# STM32H757_CM7 register map
File version: 1.3
CPU: CM7 r0p1, little endian, MPU, FPU, 4 interrupt priority bits
Registers are 32-bit, read-write, reset 0x0 unless marked. A register's access mark holds for its fields unless they carry their own. Offsets are from the block's base; [hi:lo] are bit positions; 'fields as' and 'values as' point back to an identical list.

## ADC3_Common — Analog-to-Digital Converter
Base 0x58026300
Same registers: ADC12_Common 0x40022300
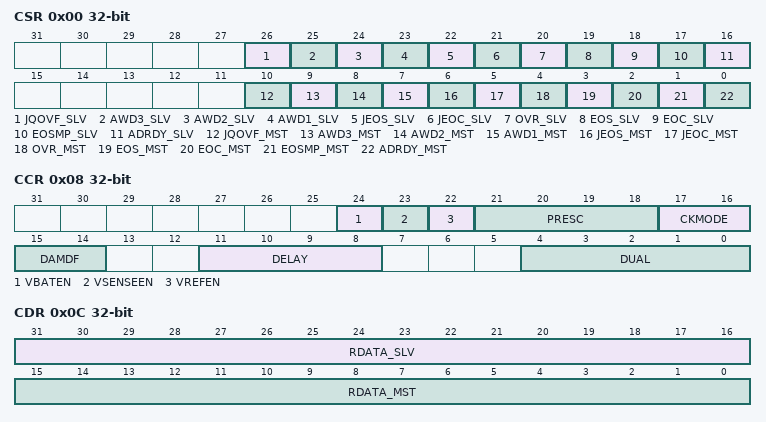
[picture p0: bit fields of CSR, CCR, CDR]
0x00 CSR ro — ADC Common status register
  [26] JQOVF_SLV — Injected Context Queue Overflow flag of the slave ADC
    0=NoOverflow (No injected context queue overflow has occurred); 1=Overflow (Injected context queue overflow has occurred)
  [25] AWD3_SLV — Analog watchdog 3 flag of the slave ADC
    0=NoEvent (No analog watchdog event occurred); 1=Event (Analog watchdog event occurred)
  [24] AWD2_SLV — Analog watchdog 2 flag of the slave ADC
    values as AWD3_SLV
  [23] AWD1_SLV — Analog watchdog 1 flag of the slave ADC
    values as AWD3_SLV
  [22] JEOS_SLV — End of injected sequence flag of the slave ADC
    0=NotComplete (Injected sequence is not complete); 1=Complete (Injected sequence complete)
  [21] JEOC_SLV — End of injected conversion flag of the slave ADC
    0=NotComplete (Injected conversion is not complete); 1=Complete (Injected conversion complete)
  [20] OVR_SLV — Overrun flag of the slave ADC
    0=No overrun occurred; 1=Overrun occurred
  [19] EOS_SLV — End of regular sequence flag of the slave ADC
    0=NotComplete (Regular sequence is not complete); 1=Complete (Regular sequence complete)
  [18] EOC_SLV — End of regular conversion of the slave ADC
    0=NotComplete (Regular conversion is not complete); 1=Complete (Regular conversion complete)
  [17] EOSMP_SLV — End of Sampling phase flag of the slave ADC
    0=NotEnded (End of sampling phase no yet reached); 1=Ended (End of sampling phase reached)
  [16] ADRDY_SLV — Slave ADC ready
    0=NotReady (ADC is not ready to start conversion); 1=Ready (ADC is ready to start conversion)
  [10] JQOVF_MST — Injected Context Queue Overflow flag of the master ADC
    values as JQOVF_SLV
  [9] AWD3_MST — Analog watchdog 3 flag of the master ADC
    values as AWD3_SLV
  [8] AWD2_MST — Analog watchdog 2 flag of the master ADC
    values as AWD3_SLV
  [7] AWD1_MST — Analog watchdog 1 flag of the master ADC
    values as AWD3_SLV
  [6] JEOS_MST — End of injected sequence flag of the master ADC
    values as JEOS_SLV
  [5] JEOC_MST — End of injected conversion flag of the master ADC
    values as JEOC_SLV
  [4] OVR_MST — Overrun flag of the master ADC
    0=No overrun occurred; 1=Overrun occurred
  [3] EOS_MST — End of regular sequence flag of the master ADC
    values as EOS_SLV
  [2] EOC_MST — End of regular conversion of the master ADC
    values as EOC_SLV
  [1] EOSMP_MST — End of Sampling phase flag of the master ADC
    values as EOSMP_SLV
  [0] ADRDY_MST — Master ADC ready
    values as ADRDY_SLV
0x08 CCR — ADC common control register
  [24] VBATEN — VBAT enable
    0=Disabled (V_BAT channel disabled); 1=Enabled (V_BAT channel enabled)
  [23] VSENSEEN — Temperature sensor enable
    0=Disabled (Temperature sensor channel disabled); 1=Enabled (Temperature sensor channel enabled)
  [22] VREFEN — VREFINT enable
    0=Disabled (V_REFINT channel disabled); 1=Enabled (V_REFINT channel enabled)
  [21:18] PRESC — ADC prescaler
    0=Div1 (adc_ker_ck_input not divided); 1=Div2 (adc_ker_ck_input divided by 2); 2=Div4 (adc_ker_ck_input divided by 4); 3=Div6 (adc_ker_ck_input divided by 6); 4=Div8 (adc_ker_ck_input divided by 8); 5=Div10 (adc_ker_ck_input divided by 10); 6=Div12 (adc_ker_ck_input divided by 12); 7=Div16 (adc_ker_ck_input divided by 16); 8=Div32 (adc_ker_ck_input divided by 32); 9=Div64 (adc_ker_ck_input divided by 64); 10=Div128 (adc_ker_ck_input divided by 128); 11=Div256 (adc_ker_ck_input divided by 256)
  [17:16] CKMODE — ADC clock mode
    0=Asynchronous (Use Kernel Clock adc_ker_ck_input divided by PRESC. Asynchronous to AHB clock); 1=SyncDiv1 (Use AHB clock rcc_hclk3. In this case rcc_hclk must equal sys_d1cpre_ck); 2=SyncDiv2 (Use AHB clock rcc_hclk3 divided by 2); 3=SyncDiv4 (Use AHB clock rcc_hclk3 divided by 4)
  [15:14] DAMDF — Dual ADC Mode Data Format
    0=NoPack (Without data packing, CDR/CDR2 not used); 2=Format32to10 (CDR formatted for 32-bit down to 10-bit resolution); 3=Format8 (CDR formatted for 8-bit resolution)
  [11:8] DELAY — Delay between 2 sampling phases
  [4:0] DUAL — Dual ADC mode selection
    0=Independent mode; 1=DualRJ (Dual, combined regular simultaneous + injected simultaneous mode); 2=DualRA (Dual, combined regular simultaneous + alternate trigger mode); 3=DualIJ (Dual, combined interleaved mode + injected simultaneous mode); 5=DualJ (Dual, injected simultaneous mode only); 6=Dual, regular simultaneous mode only; 7=Dual, interleaved mode only; 9=Dual, alternate trigger mode only
0x0C CDR ro — ADC common regular data register for dual and triple modes
  [31:16] RDATA_SLV — Regular data of the slave ADC
  [15:0] RDATA_MST — Regular data of the master ADC
0x10 CDR2 ro — ADC x common regular data register for 32-bit dual mode
  [31:0] RDATA_ALT — Regular data of the master/slave alternated ADCs
